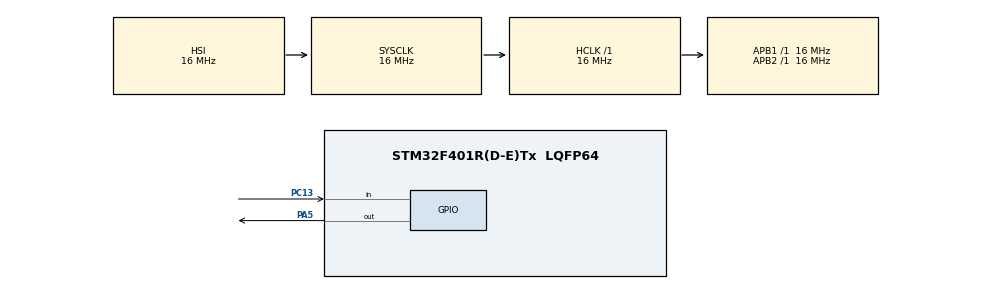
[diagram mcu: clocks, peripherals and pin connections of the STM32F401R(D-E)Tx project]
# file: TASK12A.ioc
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Mcu.Family=STM32F4
Mcu.Name=STM32F401R(D-E)Tx
Mcu.Package=LQFP64
NVIC.PriorityGroup=NVIC_PRIORITYGROUP_4
PA13.Mode=Serial_Wire
PA13.Signal=SYS_JTMS-SWDIO
PA14.Mode=Serial_Wire
PA14.Signal=SYS_JTCK-SWCLK
PA5.Signal=GPIO_Output
PC13-ANTI_TAMP.Signal=GPIO_Input
ProjectManager.HeapSize=0x200
ProjectManager.StackSize=0x400
ProjectManager.TargetToolchain=MDK-ARM V5.32
RCC.AHBFreq_Value=16000000
RCC.APB1Freq_Value=16000000
RCC.APB2Freq_Value=16000000
RCC.CortexFreq_Value=16000000
RCC.HSE_VALUE=25000000
RCC.HSI_VALUE=16000000
RCC.LSE_VALUE=32768
RCC.SYSCLKFreq_VALUE=16000000
RCC.VCOOutputFreq_Value=192000000
board=custom

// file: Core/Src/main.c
/* USER CODE BEGIN Header */
/**
  ******************************************************************************
  * @file           : main.c
  * @brief          : CAT 11 - TASK 11A: User LED LD2 Bring-Up
  * Target Device   : STM32F401RET6 (NUCLEO-F401RE, ARM Cortex-M4 @ 84 MHz)
  * Pin Map         : PA5 -> Onboard Green LED LD2 (Active-HIGH)
  ******************************************************************************
  */
/* USER CODE END Header */
#include "main.h"

void SystemClock_Config(void);
static void MX_GPIO_Init(void);

int main(void)
{

  /* MCU Configuration--------------------------------------------------------*/

  /* Reset of all peripherals, Initializes the Flash interface and the Systick. */
  HAL_Init();

  /* Configure the system clock */
  SystemClock_Config();

  /* Initialize all configured peripherals */
  MX_GPIO_Init();
  /* USER CODE BEGIN 2 */
  /* Ensure LED is initially OFF */
  HAL_GPIO_WritePin(GPIOA, GPIO_PIN_5, GPIO_PIN_RESET);
  /* USER CODE END 2 */

  /* Infinite loop */
  /* USER CODE BEGIN WHILE */
  while (1)
  {
    /* 1 Hz LED Blink: 500 ms ON, 500 ms OFF */
    HAL_GPIO_TogglePin(GPIOA, GPIO_PIN_5);
    HAL_Delay(500);
    /* USER CODE END WHILE */

  }
}

void SystemClock_Config(void)
{
  RCC_OscInitTypeDef RCC_OscInitStruct = {0};
  RCC_ClkInitTypeDef RCC_ClkInitStruct = {0};

  __HAL_RCC_PWR_CLK_ENABLE();
  __HAL_PWR_VOLTAGESCALING_CONFIG(PWR_REGULATOR_VOLTAGE_SCALE2);

  RCC_OscInitStruct.OscillatorType = RCC_OSCILLATORTYPE_HSI;
  RCC_OscInitStruct.HSIState = RCC_HSI_ON;
  RCC_OscInitStruct.HSICalibrationValue = RCC_HSICALIBRATION_DEFAULT;
  RCC_OscInitStruct.PLL.PLLState = RCC_PLL_NONE;
  if (HAL_RCC_OscConfig(&RCC_OscInitStruct) != HAL_OK)
  {
    Error_Handler();
  }

  RCC_ClkInitStruct.ClockType = RCC_CLOCKTYPE_HCLK|RCC_CLOCKTYPE_SYSCLK
                              |RCC_CLOCKTYPE_PCLK1|RCC_CLOCKTYPE_PCLK2;
  RCC_ClkInitStruct.SYSCLKSource = RCC_SYSCLKSOURCE_HSI;
  RCC_ClkInitStruct.AHBCLKDivider = RCC_SYSCLK_DIV1;
  RCC_ClkInitStruct.APB1CLKDivider = RCC_HCLK_DIV1;
  RCC_ClkInitStruct.APB2CLKDivider = RCC_HCLK_DIV1;

  if (HAL_RCC_ClockConfig(&RCC_ClkInitStruct, FLASH_LATENCY_0) != HAL_OK)
  {
    Error_Handler();
  }
}

static void MX_GPIO_Init(void)
{
  GPIO_InitTypeDef GPIO_InitStruct = {0};

  /* GPIO Ports Clock Enable */
  __HAL_RCC_GPIOA_CLK_ENABLE();

  /* Configure GPIO pin Output Level */
  HAL_GPIO_WritePin(GPIOA, GPIO_PIN_5, GPIO_PIN_RESET);

  /* Configure GPIO pin : PA5 (LD2 Green LED) */
  GPIO_InitStruct.Pin = GPIO_PIN_5;
  GPIO_InitStruct.Mode = GPIO_MODE_OUTPUT_PP;
  GPIO_InitStruct.Pull = GPIO_NOPULL;
  GPIO_InitStruct.Speed = GPIO_SPEED_FREQ_LOW;
  HAL_GPIO_Init(GPIOA, &GPIO_InitStruct);
}

void Error_Handler(void)
{
  __disable_irq();
  while (1)
  {
  }
}
